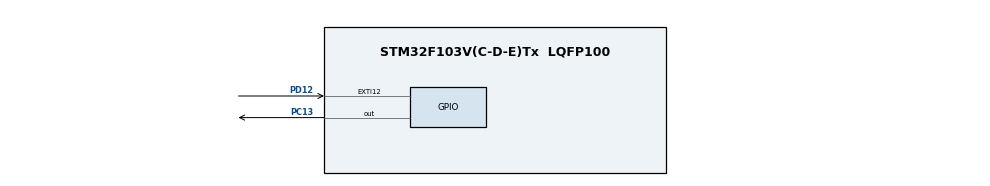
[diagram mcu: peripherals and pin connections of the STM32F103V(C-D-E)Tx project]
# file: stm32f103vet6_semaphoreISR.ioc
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FREERTOS.BinarySemaphores01=ButtonSemaphore,Dynamic,NULL,Available
FREERTOS.Tasks01=LedTask,0,128,StartDefaultTask,Default,NULL,Dynamic,NULL,NULL
Mcu.Family=STM32F1
Mcu.Name=STM32F103V(C-D-E)Tx
Mcu.Package=LQFP100
NVIC.EXTI15_10_IRQn=true\:5\:0\:false\:false\:true\:true\:true\:true\:true
NVIC.PriorityGroup=NVIC_PRIORITYGROUP_4
OSC_IN.Mode=HSE-External-Oscillator
OSC_IN.Signal=RCC_OSC_IN
OSC_OUT.Mode=HSE-External-Oscillator
OSC_OUT.Signal=RCC_OSC_OUT
PA13.Mode=Serial_Wire
PA13.Signal=SYS_JTMS-SWDIO
PA14.Mode=Serial_Wire
PA14.Signal=SYS_JTCK-SWCLK
PC13-TAMPER-RTC.Signal=GPIO_Output
PD12.Signal=GPXTI12
ProjectManager.HeapSize=0x200
ProjectManager.StackSize=0x400
ProjectManager.TargetToolchain=STM32CubeIDE
RCC.APB1Freq_Value=8000000
RCC.APB2Freq_Value=8000000
VP_FREERTOS_VS_CMSIS_V1.Mode=CMSIS_V1
board=custom

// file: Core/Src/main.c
/* USER CODE BEGIN Header */
/**
  ******************************************************************************
  * @file           : main.c
  * @brief          : Main program body
  ******************************************************************************
  * @attention
  *
  * Copyright (c) 2026 STMicroelectronics.
  * All rights reserved.
  *
  * This software is licensed under terms that can be found in the LICENSE file
  * in the root directory of this software component.
  * If no LICENSE file comes with this software, it is provided AS-IS.
  *
  ******************************************************************************
  */
/* USER CODE END Header */
#include "main.h"
#include "cmsis_os.h"

osThreadId LedTaskHandle;
osSemaphoreId ButtonSemaphoreHandle;

void SystemClock_Config(void);
static void MX_GPIO_Init(void);
void StartDefaultTask(void const * argument);

int main(void)
{

  /* MCU Configuration--------------------------------------------------------*/

  /* Reset of all peripherals, Initializes the Flash interface and the Systick. */
  HAL_Init();

  /* Configure the system clock */
  SystemClock_Config();

  /* Initialize all configured peripherals */
  MX_GPIO_Init();

  /* Create the semaphores(s) */
  /* definition and creation of ButtonSemaphore */
  osSemaphoreDef(ButtonSemaphore);
  ButtonSemaphoreHandle = osSemaphoreCreate(osSemaphore(ButtonSemaphore), 1);

  /* Create the thread(s) */
  /* definition and creation of LedTask */
  osThreadDef(LedTask, StartDefaultTask, osPriorityNormal, 0, 128);
  LedTaskHandle = osThreadCreate(osThread(LedTask), NULL);

  /* Start scheduler */
  osKernelStart();

  /* We should never get here as control is now taken by the scheduler */

  /* Infinite loop */
  while (1)
  {

  }
}

void SystemClock_Config(void)
{
  RCC_OscInitTypeDef RCC_OscInitStruct = {0};
  RCC_ClkInitTypeDef RCC_ClkInitStruct = {0};

  /** Initializes the RCC Oscillators according to the specified parameters
  * in the RCC_OscInitTypeDef structure.
  */
  RCC_OscInitStruct.OscillatorType = RCC_OSCILLATORTYPE_HSI;
  RCC_OscInitStruct.HSIState = RCC_HSI_ON;
  RCC_OscInitStruct.HSICalibrationValue = RCC_HSICALIBRATION_DEFAULT;
  RCC_OscInitStruct.PLL.PLLState = RCC_PLL_NONE;
  if (HAL_RCC_OscConfig(&RCC_OscInitStruct) != HAL_OK)
  {
    Error_Handler();
  }

  /** Initializes the CPU, AHB and APB buses clocks
  */
  RCC_ClkInitStruct.ClockType = RCC_CLOCKTYPE_HCLK|RCC_CLOCKTYPE_SYSCLK
                              |RCC_CLOCKTYPE_PCLK1|RCC_CLOCKTYPE_PCLK2;
  RCC_ClkInitStruct.SYSCLKSource = RCC_SYSCLKSOURCE_HSI;
  RCC_ClkInitStruct.AHBCLKDivider = RCC_SYSCLK_DIV1;
  RCC_ClkInitStruct.APB1CLKDivider = RCC_HCLK_DIV1;
  RCC_ClkInitStruct.APB2CLKDivider = RCC_HCLK_DIV1;

  if (HAL_RCC_ClockConfig(&RCC_ClkInitStruct, FLASH_LATENCY_0) != HAL_OK)
  {
    Error_Handler();
  }
}

static void MX_GPIO_Init(void)
{
  GPIO_InitTypeDef GPIO_InitStruct = {0};

  /* GPIO Ports Clock Enable */
  __HAL_RCC_GPIOC_CLK_ENABLE();
  __HAL_RCC_GPIOD_CLK_ENABLE();
  __HAL_RCC_GPIOA_CLK_ENABLE();

  /*Configure GPIO pin Output Level */
  HAL_GPIO_WritePin(GPIOC, GPIO_PIN_13, GPIO_PIN_RESET);

  /*Configure GPIO pin : PC13 */
  GPIO_InitStruct.Pin = GPIO_PIN_13;
  GPIO_InitStruct.Mode = GPIO_MODE_OUTPUT_PP;
  GPIO_InitStruct.Pull = GPIO_NOPULL;
  GPIO_InitStruct.Speed = GPIO_SPEED_FREQ_LOW;
  HAL_GPIO_Init(GPIOC, &GPIO_InitStruct);

  /*Configure GPIO pin : PD12 */
  GPIO_InitStruct.Pin = GPIO_PIN_12;
  GPIO_InitStruct.Mode = GPIO_MODE_IT_FALLING;
  GPIO_InitStruct.Pull = GPIO_PULLUP;
  HAL_GPIO_Init(GPIOD, &GPIO_InitStruct);

  /* EXTI interrupt init*/
  HAL_NVIC_SetPriority(EXTI15_10_IRQn, 5, 0);
  HAL_NVIC_EnableIRQ(EXTI15_10_IRQn);

}

/* USER CODE BEGIN 4 */
void HAL_GPIO_EXTI_Callback(uint16_t GPIO_Pin)
{
	if(GPIO_Pin == GPIO_PIN_12)
	  {
	    BaseType_t xHigherPriorityTaskWoken = pdFALSE;
	    vTaskNotifyGiveFromISR((TaskHandle_t)LedTaskHandle, &xHigherPriorityTaskWoken);
	    portYIELD_FROM_ISR(xHigherPriorityTaskWoken);
	  }
}

/* USER CODE END 4 */

void StartDefaultTask(void const * argument)
{
  /* USER CODE BEGIN 5 */
  /* Infinite loop */
  for(;;)
  {
	  ulTaskNotifyTake(pdTRUE, portMAX_DELAY);
	  HAL_GPIO_TogglePin(GPIOC, GPIO_PIN_13);
	  osDelay(200);

  }
  /* USER CODE END 5 */
}

void Error_Handler(void)
{
  __disable_irq();
  while (1)
  {
  }
}
